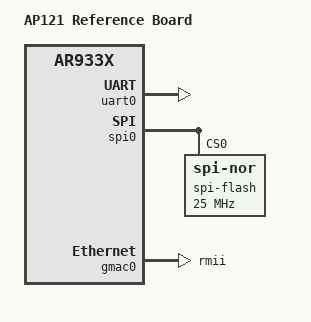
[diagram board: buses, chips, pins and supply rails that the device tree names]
// SPDX-License-Identifier: GPL-2.0+
/*
 * Copyright (C) 2015-2016 Wills Wang <wills.wang@live.com>
 */

/dts-v1/;
#include "ar933x.dtsi"

/ {
	model = "AP121 Reference Board";
	compatible = "qca,ap121", "qca,ar933x";

	aliases {
		spi0 = &spi0;
		serial0 = &uart0;
	};

	chosen {
		stdout-path = "serial0:115200n8";
	};
};

&xtal {
	clock-frequency = <25000000>;
};

&uart0 {
	status = "okay";
};

&spi0 {
	spi-max-frequency = <25000000>;
	status = "okay";
	spi-flash@0 {
		#address-cells = <1>;
		#size-cells = <1>;
		compatible = "jedec,spi-nor";
		memory-map = <0x9f000000 0x00800000>;
		spi-max-frequency = <25000000>;
		reg = <0>;
	};
};

&gmac0 {
	phy-mode = "rmii";
	status = "okay";
};
